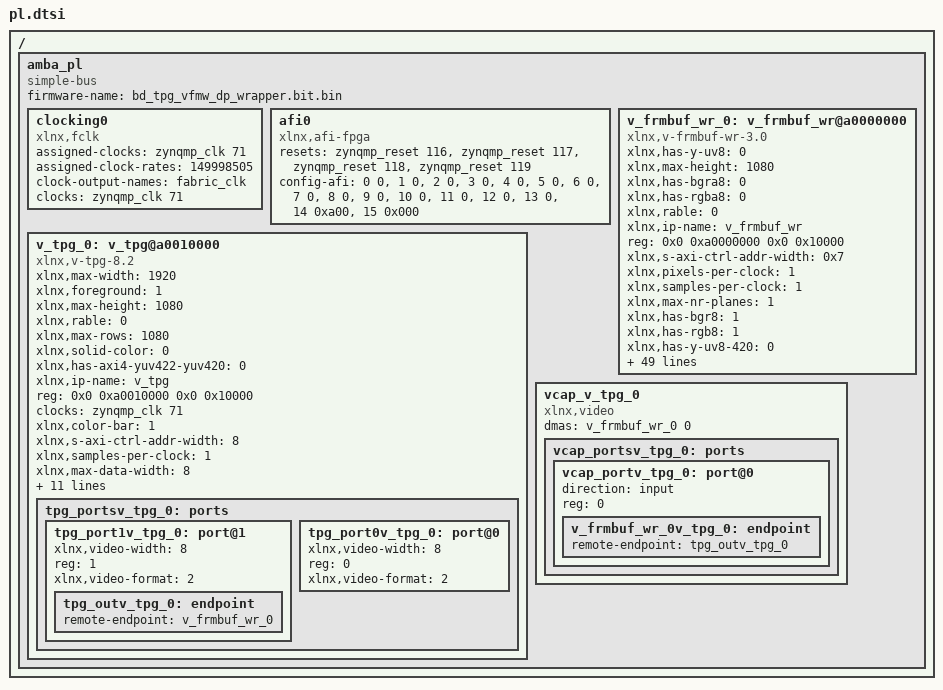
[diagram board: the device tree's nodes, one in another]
/ {
	amba_pl: amba_pl {
		ranges;
		compatible = "simple-bus";
		#address-cells = <2>;
		#size-cells = <2>;
		firmware-name = "bd_tpg_vfmw_dp_wrapper.bit.bin";
		clocking0: clocking0 {
			compatible = "xlnx,fclk";
			status = "okay";
			assigned-clocks = <&zynqmp_clk 71>;
			assigned-clock-rates = <149998505>;
			#clock-cells = <0>;
			clock-output-names = "fabric_clk";
			clocks = <&zynqmp_clk 71>;
		};
		afi0: afi0 {
			status = "okay";
			compatible = "xlnx,afi-fpga";
			resets = <&zynqmp_reset 116>, <&zynqmp_reset 117>, <&zynqmp_reset 118>, <&zynqmp_reset 119>;
			config-afi = < 0 0>, <1 0>, <2 0>, <3 0>, <4 0>, <5 0>, <6 0>, <7 0>, <8 0>, <9 0>, <10 0>, <11 0>, <12 0>, <13 0>, <14 0xa00>, <15 0x000>;
		};
		v_frmbuf_wr_0: v_frmbuf_wr@a0000000 {
			xlnx,has-y-uv8 = <0>;
			xlnx,max-height = <1080>;
			xlnx,has-bgra8 = <0>;
			xlnx,has-rgba8 = <0>;
			xlnx,rable = <0>;
			xlnx,ip-name = "v_frmbuf_wr";
			reg = <0x0 0xa0000000 0x0 0x10000>;
			xlnx,s-axi-ctrl-addr-width = <0x7>;
			xlnx,pixels-per-clock = <1>;
			xlnx,samples-per-clock = <1>;
			xlnx,max-nr-planes = <1>;
			xlnx,has-bgr8 = <1>;
			xlnx,has-rgb8 = <1>;
			xlnx,has-y-uv8-420 = <0>;
			xlnx,has-yuyv8 = <0>;
			xlnx,has-y-u-v8 = <0>;
			interrupt-names = "interrupt";
			compatible = "xlnx,v-frmbuf-wr-3.0" , "xlnx,axi-frmbuf-wr-v2.2";
			xlnx,max-width = <1920>;
			xlnx,has-rgb16 = <0>;
			xlnx,vid-formats = "rgb888" , "bgr888";
			xlnx,has-bgrx8 = <0>;
			xlnx,has-rgbx8 = <0>;
			xlnx,has-rgbx10 = <0>;
			interrupt-parent = <&imux>;
			xlnx,aximm-num-outstanding = <4>;
			xlnx,has-uyvy8 = <0>;
			xlnx,has-rgbx12 = <0>;
			xlnx,aximm-burst-length = <16>;
			xlnx,aximm-addr-width = <32>;
			xlnx,video-width = <8>;
			xlnx,max-cols = <1920>;
			xlnx,has-yuv8 = <0>;
			status = "okay";
			xlnx,has-y-uv10-420 = <0>;
			xlnx,has-yuva8 = <0>;
			xlnx,has-y-uv12-420 = <0>;
			xlnx,name = "v_frmbuf_wr_0";
			interrupts = < 0 89 4 >;
			xlnx,has-y10 = <0>;
			xlnx,has-y-uv16-420 = <0>;
			xlnx,has-y12 = <0>;
			xlnx,has-alpha = <0>;
			xlnx,has-y-u-v10 = <0>;
			clocks = <&zynqmp_clk 71>;
			xlnx,has-y16 = <0>;
			xlnx,dma-align = <8>;
			xlnx,has-y-u-v12 = <0>;
			xlnx,edk-iptype = "PERIPHERAL";
			xlnx,has-interlaced = <0>;
			xlnx,has-yuv16 = <0>;
			xlnx,has-yuvx8 = <0>;
			xlnx,is-tile-format = <0>;
			xlnx,dma-addr-width = <32>;
			clock-names = "ap_clk";
			xlnx,s-axi-ctrl-data-width = <0x20>;
			xlnx,has-y8 = <0>;
			xlnx,has-y-uv10 = <0>;
			xlnx,has-y-uv12 = <0>;
			xlnx,max-rows = <1080>;
			xlnx,has-yuvx10 = <0>;
			#dma-cells = <1>;
			xlnx,has-yuvx12 = <0>;
			xlnx,has-y-uv16 = <0>;
			xlnx,max-data-width = <8>;
			xlnx,has-y-u-v8-420 = <0>;
			xlnx,num-video-components = <3>;
			xlnx,aximm-data-width = <64>;
		};
		v_tpg_0: v_tpg@a0010000 {
			compatible = "xlnx,v-tpg-8.2" , "xlnx,v-tpg-8.0";
			xlnx,max-width = <1920>;
			xlnx,foreground = <1>;
			xlnx,max-height = <1080>;
			xlnx,rable = <0>;
			xlnx,max-rows = <1080>;
			xlnx,solid-color = <0>;
			xlnx,has-axi4-yuv422-yuv420 = <0>;
			xlnx,ip-name = "v_tpg";
			reg = <0x0 0xa0010000 0x0 0x10000>;
			clocks = <&zynqmp_clk 71>;
			xlnx,color-bar = <1>;
			xlnx,s-axi-ctrl-addr-width = <8>;
			xlnx,samples-per-clock = <1>;
			xlnx,max-data-width = <8>;
			xlnx,has-axi4s-slave = <0>;
			xlnx,ppc = <1>;
			xlnx,max-cols = <1920>;
			xlnx,edk-iptype = "PERIPHERAL";
			status = "okay";
			clock-names = "ap_clk";
			xlnx,zone-plate = <0>;
			xlnx,num-video-components = <3>;
			xlnx,ramp = <0>;
			xlnx,color-sweep = <0>;
			xlnx,s-axi-ctrl-data-width = <32>;
			xlnx,display-port = <0>;
			xlnx,name = "v_tpg_0";
			tpg_portsv_tpg_0: ports {
				#address-cells = <1>;
				#size-cells = <0>;
				tpg_port1v_tpg_0: port@1 {
					xlnx,video-width = <8>;
					reg = <1>;
					xlnx,video-format = <2>;
					tpg_outv_tpg_0: endpoint {
						remote-endpoint = <&v_frmbuf_wr_0>;
					};
				};
				tpg_port0v_tpg_0: port@0 {
					xlnx,video-width = <8>;
					reg = <0>;
					xlnx,video-format = <2>;
				};
			};
		};
		vcap_v_tpg_0 {
			compatible = "xlnx,video";
			dmas = <&v_frmbuf_wr_0 0>;
			dma-names = "port0";
			vcap_portsv_tpg_0: ports {
				#address-cells = <1>;
				#size-cells = <0>;
				vcap_portv_tpg_0: port@0 {
					direction = "input";
					reg = <0>;
					v_frmbuf_wr_0v_tpg_0: endpoint {
						remote-endpoint = <&tpg_outv_tpg_0>;
					};
				};
			};
		};
	};
};
